AUTOSAR XML (schema 4-2-2)
package /ComponentTypes
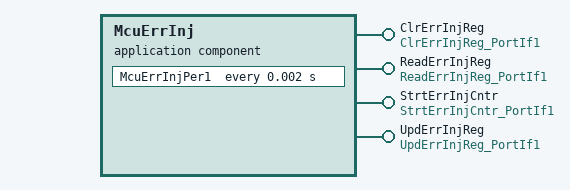
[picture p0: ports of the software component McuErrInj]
  application sw component type McuErrInj
    4 x provide port, all with server-com-spec{operation=Oper, queue-length=1}:
      ClrErrInjReg: provided-interface=ClrErrInjReg_PortIf1
      ReadErrInjReg: provided-interface=ReadErrInjReg_PortIf1
      StrtErrInjCntr: provided-interface=StrtErrInjCntr_PortIf1
      UpdErrInjReg: provided-interface=UpdErrInjReg_PortIf1
    behavior McuErrInj_InternalBehavior
      ar-typed-per-instance-memorys:
        data ErrInjActvCntr: sw-calibration-access=READ-ONLY, type=uint8
        data StrtErrInj: sw-calibration-access=READ-ONLY, type=boolean
      operation invoked event OIT_ClrErrInjReg_Oper_ClrErrInjReg_Oper: start-on-event=ClrErrInjReg_Oper, operation=ClrErrInjReg.Oper
      init event McuErrInj_InitEvent: start-on-event=McuErrInjInit1
      timing event TMT_McuFltInjPer1: start-on-event=McuErrInjPer1, period=0.002
      operation invoked event OIT_ReadErrInjReg_Oper_ReadErrInjReg_Oper: start-on-event=ReadErrInjReg_Oper, operation=ReadErrInjReg.Oper
      operation invoked event OIT_StrtErrInjCntr_Oper_StrtErrInjCntr_Oper: start-on-event=StrtErrInjCntr_Oper, operation=StrtErrInjCntr.Oper
      operation invoked event OIT_UpdErrInjReg_Oper_UpdErrInjReg_Oper: start-on-event=UpdErrInjReg_Oper, operation=UpdErrInjReg.Oper
      6 x runnable:
        ClrErrInjReg_Oper
        McuErrInjInit1
        McuErrInjPer1
        ReadErrInjReg_Oper: can-be-invoked-concurrently=true
        StrtErrInjCntr_Oper
        UpdErrInjReg_Oper
  swc implementation McuErrInj_Implementation: behavior=McuErrInj_InternalBehavior
    code-descriptors:
      code Default: artifact-descriptors=autosar-engineering-object={short-label=Default, category=SWSRC}
